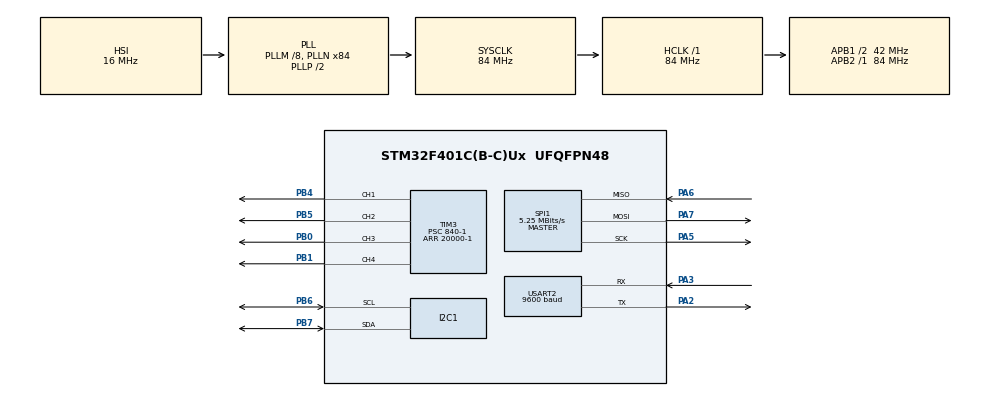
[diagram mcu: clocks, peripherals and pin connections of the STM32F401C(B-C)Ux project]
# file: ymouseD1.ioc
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Dma.Request0=USART2_TX
Dma.USART2_TX.0.Direction=DMA_MEMORY_TO_PERIPH
Dma.USART2_TX.0.FIFOMode=DMA_FIFOMODE_DISABLE
Dma.USART2_TX.0.Instance=DMA1_Stream6
Dma.USART2_TX.0.MemDataAlignment=DMA_MDATAALIGN_BYTE
Dma.USART2_TX.0.MemInc=DMA_MINC_ENABLE
Dma.USART2_TX.0.Mode=DMA_NORMAL
Dma.USART2_TX.0.PeriphDataAlignment=DMA_PDATAALIGN_BYTE
Dma.USART2_TX.0.PeriphInc=DMA_PINC_DISABLE
Dma.USART2_TX.0.Priority=DMA_PRIORITY_HIGH
FREERTOS.Tasks01=defaultTask,8,128,StartDefaultTask,Default,NULL,Dynamic,NULL,NULL;master,40,512,master_task,As external,NULL,Dynamic,NULL,NULL;imu,24,512,imu_task,As external,NULL,Dynamic,NULL,NULL;message,8,512,message_task,As external,NULL,Dynamic,NULL,NULL
FREERTOS.configCHECK_FOR_STACK_OVERFLOW=2
FREERTOS.configENABLE_FPU=1
FREERTOS.configTOTAL_HEAP_SIZE=16384
FREERTOS.configUSE_MALLOC_FAILED_HOOK=1
Mcu.Family=STM32F4
Mcu.Name=STM32F401C(B-C)Ux
Mcu.Package=UFQFPN48
NVIC.DMA1_Stream6_IRQn=true\:5\:0\:false\:false\:true\:true\:false\:true\:true
NVIC.PriorityGroup=NVIC_PRIORITYGROUP_4
NVIC.TIM1_UP_TIM10_IRQn=true\:15\:0\:false\:false\:true\:false\:false\:true\:true
NVIC.TimeBase=TIM1_UP_TIM10_IRQn
NVIC.TimeBaseIP=TIM1
NVIC.USART2_IRQn=true\:5\:0\:false\:false\:true\:true\:false\:true\:true
PA13.Mode=Serial_Wire
PA13.Signal=SYS_JTMS-SWDIO
PA14.Mode=Serial_Wire
PA14.Signal=SYS_JTCK-SWCLK
PA2.Mode=Asynchronous
PA2.Signal=USART2_TX
PA3.Mode=Asynchronous
PA3.Signal=USART2_RX
PA5.Mode=Full_Duplex_Master
PA5.Signal=SPI1_SCK
PA6.Mode=Full_Duplex_Master
PA6.Signal=SPI1_MISO
PA7.Mode=Full_Duplex_Master
PA7.Signal=SPI1_MOSI
PB0.Signal=S_TIM3_CH3
PB1.Signal=S_TIM3_CH4
PB4.Signal=S_TIM3_CH1
PB5.Signal=S_TIM3_CH2
PB6.GPIO_Pu=GPIO_PULLUP
PB6.Mode=I2C
PB6.Signal=I2C1_SCL
PB7.GPIO_Pu=GPIO_PULLUP
PB7.Mode=I2C
PB7.Signal=I2C1_SDA
PH0\ -\ OSC_IN.Mode=HSE-External-Oscillator
PH0\ -\ OSC_IN.Signal=RCC_OSC_IN
PH1\ -\ OSC_OUT.Mode=HSE-External-Oscillator
PH1\ -\ OSC_OUT.Signal=RCC_OSC_OUT
ProjectManager.HeapSize=0x400
ProjectManager.StackSize=0x400
ProjectManager.TargetToolchain=CMake
RCC.48MHZClocksFreq_Value=42000000
RCC.AHBFreq_Value=84000000
RCC.APB1CLKDivider=RCC_HCLK_DIV2
RCC.APB1Freq_Value=42000000
RCC.APB1TimFreq_Value=84000000
RCC.APB2Freq_Value=84000000
RCC.APB2TimFreq_Value=84000000
RCC.CortexFreq_Value=84000000
RCC.HCLKFreq_Value=84000000
RCC.HSE_VALUE=25000000
RCC.HSI_VALUE=16000000
RCC.LSE_VALUE=32768
RCC.PLLM=8
RCC.PLLN=84
RCC.SYSCLKFreq_VALUE=84000000
RCC.SYSCLKSource=RCC_SYSCLKSOURCE_PLLCLK
RCC.VCOOutputFreq_Value=168000000
SH.S_TIM3_CH1.0=TIM3_CH1,PWM Generation1 CH1
SH.S_TIM3_CH2.0=TIM3_CH2,PWM Generation2 CH2
SH.S_TIM3_CH3.0=TIM3_CH3,PWM Generation3 CH3
SH.S_TIM3_CH4.0=TIM3_CH4,PWM Generation4 CH4
SPI1.BaudRatePrescaler=SPI_BAUDRATEPRESCALER_16
SPI1.CLKPolarity=SPI_POLARITY_LOW
SPI1.CRCCalculation=SPI_CRCCALCULATION_DISABLE
SPI1.CalculateBaudRate=5.25 MBits/s
SPI1.Direction=SPI_DIRECTION_2LINES
SPI1.Mode=SPI_MODE_MASTER
SPI1.VirtualType=VM_MASTER
TIM3.Channel-PWM\ Generation1\ CH1=TIM_CHANNEL_1
TIM3.Channel-PWM\ Generation2\ CH2=TIM_CHANNEL_2
TIM3.Channel-PWM\ Generation3\ CH3=TIM_CHANNEL_3
TIM3.Channel-PWM\ Generation4\ CH4=TIM_CHANNEL_4
TIM3.Period=20000-1
TIM3.Prescaler=840-1
USART2.BaudRate=9600
USART2.VirtualMode=VM_ASYNC
VP_FREERTOS_VS_CMSIS_V2.Mode=CMSIS_V2
VP_SYS_VS_tim1.Mode=TIM1
board=custom

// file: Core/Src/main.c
/* USER CODE BEGIN Header */
/**
  ******************************************************************************
  * @file           : main.c
  * @brief          : Main program body
  ******************************************************************************
  * @attention
  *
  * Copyright (c) 2026 STMicroelectronics.
  * All rights reserved.
  *
  * This software is licensed under terms that can be found in the LICENSE file
  * in the root directory of this software component.
  * If no LICENSE file comes with this software, it is provided AS-IS.
  *
  ******************************************************************************
  */
/* USER CODE END Header */
#include "main.h"
#include "cmsis_os.h"
#include "dma.h"
#include "i2c.h"
#include "spi.h"
#include "tim.h"
#include "usart.h"
#include "gpio.h"

void SystemClock_Config(void);
void MX_FREERTOS_Init(void);

int main(void)
{

  /* MCU Configuration--------------------------------------------------------*/

  /* Reset of all peripherals, Initializes the Flash interface and the Systick. */
  HAL_Init();

  /* Configure the system clock */
  SystemClock_Config();

  /* Initialize all configured peripherals */
  MX_GPIO_Init();
  MX_DMA_Init();
  MX_SPI1_Init();
  MX_USART2_UART_Init();
  MX_I2C1_Init();
  MX_TIM3_Init();

  /* Init scheduler */
  osKernelInitialize();

  /* Call init function for freertos objects (in cmsis_os2.c) */
  MX_FREERTOS_Init();

  /* Start scheduler */
  osKernelStart();

  /* We should never get here as control is now taken by the scheduler */

  /* Infinite loop */
  while (1)
  {

  }
}

void SystemClock_Config(void)
{
  RCC_OscInitTypeDef RCC_OscInitStruct = {0};
  RCC_ClkInitTypeDef RCC_ClkInitStruct = {0};

  /** Configure the main internal regulator output voltage
  */
  __HAL_RCC_PWR_CLK_ENABLE();
  __HAL_PWR_VOLTAGESCALING_CONFIG(PWR_REGULATOR_VOLTAGE_SCALE2);

  /** Initializes the RCC Oscillators according to the specified parameters
  * in the RCC_OscInitTypeDef structure.
  */
  RCC_OscInitStruct.OscillatorType = RCC_OSCILLATORTYPE_HSI;
  RCC_OscInitStruct.HSIState = RCC_HSI_ON;
  RCC_OscInitStruct.HSICalibrationValue = RCC_HSICALIBRATION_DEFAULT;
  RCC_OscInitStruct.PLL.PLLState = RCC_PLL_ON;
  RCC_OscInitStruct.PLL.PLLSource = RCC_PLLSOURCE_HSI;
  RCC_OscInitStruct.PLL.PLLM = 8;
  RCC_OscInitStruct.PLL.PLLN = 84;
  RCC_OscInitStruct.PLL.PLLP = RCC_PLLP_DIV2;
  RCC_OscInitStruct.PLL.PLLQ = 4;
  if (HAL_RCC_OscConfig(&RCC_OscInitStruct) != HAL_OK)
  {
    Error_Handler();
  }

  /** Initializes the CPU, AHB and APB buses clocks
  */
  RCC_ClkInitStruct.ClockType = RCC_CLOCKTYPE_HCLK|RCC_CLOCKTYPE_SYSCLK
                              |RCC_CLOCKTYPE_PCLK1|RCC_CLOCKTYPE_PCLK2;
  RCC_ClkInitStruct.SYSCLKSource = RCC_SYSCLKSOURCE_PLLCLK;
  RCC_ClkInitStruct.AHBCLKDivider = RCC_SYSCLK_DIV1;
  RCC_ClkInitStruct.APB1CLKDivider = RCC_HCLK_DIV2;
  RCC_ClkInitStruct.APB2CLKDivider = RCC_HCLK_DIV1;

  if (HAL_RCC_ClockConfig(&RCC_ClkInitStruct, FLASH_LATENCY_2) != HAL_OK)
  {
    Error_Handler();
  }
}

void HAL_TIM_PeriodElapsedCallback(TIM_HandleTypeDef *htim)
{
  if (htim->Instance == TIM1)
  {
    HAL_IncTick();
  }
}

void Error_Handler(void)
{
  __disable_irq();
  while (1)
  {
  }
}

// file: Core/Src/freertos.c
/* USER CODE BEGIN Header */
/**
  ******************************************************************************
  * File Name          : freertos.c
  * Description        : Code for freertos applications
  ******************************************************************************
  * @attention
  *
  * Copyright (c) 2026 STMicroelectronics.
  * All rights reserved.
  *
  * This software is licensed under terms that can be found in the LICENSE file
  * in the root directory of this software component.
  * If no LICENSE file comes with this software, it is provided AS-IS.
  *
  ******************************************************************************
  */
/* USER CODE END Header */

#include "FreeRTOS.h"
#include "task.h"
#include "main.h"
#include "cmsis_os.h"

/* Definitions for defaultTask */
osThreadId_t defaultTaskHandle;
const osThreadAttr_t defaultTask_attributes = {
  .name = "defaultTask",
  .stack_size = 128 * 4,
  .priority = (osPriority_t) osPriorityLow,
};
/* Definitions for master */
osThreadId_t masterHandle;
const osThreadAttr_t master_attributes = {
  .name = "master",
  .stack_size = 512 * 4,
  .priority = (osPriority_t) osPriorityHigh,
};
/* Definitions for imu */
osThreadId_t imuHandle;
const osThreadAttr_t imu_attributes = {
  .name = "imu",
  .stack_size = 512 * 4,
  .priority = (osPriority_t) osPriorityNormal,
};
/* Definitions for message */
osThreadId_t messageHandle;
const osThreadAttr_t message_attributes = {
  .name = "message",
  .stack_size = 512 * 4,
  .priority = (osPriority_t) osPriorityLow,
};

void StartDefaultTask(void *argument);
extern void master_task(void *argument);
extern void imu_task(void *argument);
extern void message_task(void *argument);

void MX_FREERTOS_Init(void); /* (MISRA C 2004 rule 8.1) */

/* Hook prototypes */
void vApplicationStackOverflowHook(xTaskHandle xTask, signed char *pcTaskName);
void vApplicationMallocFailedHook(void);

/* USER CODE BEGIN 4 */
/**
 * @brief 独立看门狗:LSI 32kHz/64=500Hz,重载 400 → 约 0.8s
 * @note  任何任务/中断把系统真正卡死时自动复位整机。
 *        调试挂起 CPU 时冻结 IWDG,断点停留不会误触发复位。
 */
static void iwdg_init(void)
{
  DBGMCU->APB1FZ |= DBGMCU_APB1_FZ_DBG_IWDG_STOP; /* 调试挂起时冻结 */
  IWDG->KR = 0x5555U;                       /* 解锁寄存器 */
  IWDG->PR = IWDG_PR_PR_1 | IWDG_PR_PR_0;   /* 64 分频 */
  IWDG->RLR = 400U;
  IWDG->KR = 0xAAAAU;                       /* 重载计数 */
  IWDG->KR = 0xCCCCU;                       /* 启动 */
}

void vApplicationStackOverflowHook(xTaskHandle xTask, signed char *pcTaskName)
{
   /* Run time stack overflow checking is performed if
   configCHECK_FOR_STACK_OVERFLOW is defined to 1 or 2. This hook function is
   called if a stack overflow is detected. */
}
/* USER CODE END 4 */

/* USER CODE BEGIN 5 */
void vApplicationMallocFailedHook(void)
{
   /* vApplicationMallocFailedHook() will only be called if
   configUSE_MALLOC_FAILED_HOOK is set to 1 in FreeRTOSConfig.h. It is a hook
   function that will get called if a call to pvPortMalloc() fails.
   pvPortMalloc() is called internally by the kernel whenever a task, queue,
   timer or semaphore is created. It is also called by various parts of the
   demo application. If heap_1.c or heap_2.c are used, then the size of the
   heap available to pvPortMalloc() is defined by configTOTAL_HEAP_SIZE in
   FreeRTOSConfig.h, and the xPortGetFreeHeapSize() API function can be used
   to query the size of free heap space that remains (although it does not
   provide information on how the remaining heap might be fragmented). */
}
/* USER CODE END 5 */

void MX_FREERTOS_Init(void) {

  /* Create the thread(s) */
  /* creation of defaultTask */
  defaultTaskHandle = osThreadNew(StartDefaultTask, NULL, &defaultTask_attributes);

  /* creation of master */
  masterHandle = osThreadNew(master_task, NULL, &master_attributes);

  /* creation of imu */
  imuHandle = osThreadNew(imu_task, NULL, &imu_attributes);

  /* creation of message */
  messageHandle = osThreadNew(message_task, NULL, &message_attributes);

}

void StartDefaultTask(void *argument)
{
  /* USER CODE BEGIN StartDefaultTask */
  iwdg_init();

  /* Infinite loop */
  for(;;)
  {
    IWDG->KR = 0xAAAAU; /* 喂狗 */
    osDelay(100);
  }
  /* USER CODE END StartDefaultTask */
}
